# EZR32HG320F64R60 register map
File version: 4.0.0
CPU: CM0PLUS r0p1, little endian, no MPU, no FPU, 3 interrupt priority bits
Registers are 32-bit, read-write, reset 0x0 unless marked. A register's access mark holds for its fields unless they carry their own. Offsets are from the block's base; [hi:lo] are bit positions; {n}, {i} and the like mark numbered series; 'fields as' and 'values as' point back to an identical list.

## USB
Base 0x400C4000
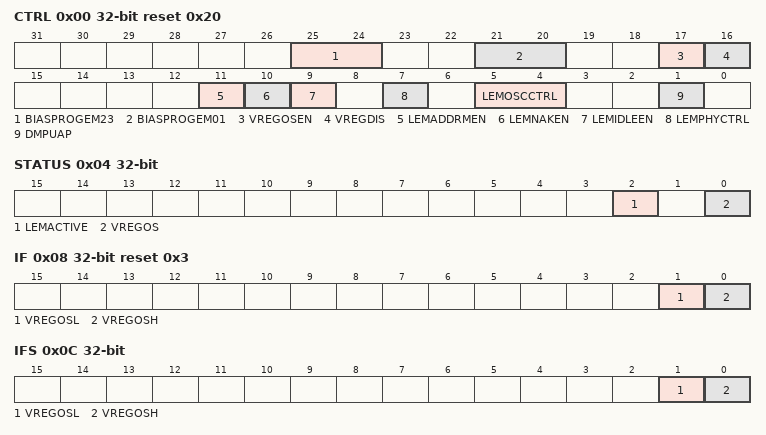
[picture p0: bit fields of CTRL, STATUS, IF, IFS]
0x00 CTRL reset 0x20 — System Control Register
  [25:24] BIASPROGEM23 — Regulator Bias Programming Value in EM2/3
  [21:20] BIASPROGEM01 — Regulator Bias Programming Value in EM0/1
  [17] VREGOSEN — VREGO Sense Enable
  [16] VREGDIS — Voltage Regulator Disable
  [11] LEMADDRMEN — Low Energy Mode on Device Address Mismatch Enable
  [10] LEMNAKEN — Low Energy Mode on OUT NAK Enable
  [9] LEMIDLEEN — Low Energy Mode on Bus Idle Enable
  [7] LEMPHYCTRL — Low Energy Mode USB PHY Control
  [5:4] LEMOSCCTRL — Low Energy Mode Oscillator Control
    0=NONE (Low Energy Mode has no effect on neither USBC or USHFRCO.); 1=GATE (The USBC clock is gated when Low Energy Mode is active.); 2=SUSPEND (The USBC clock is gated, and USHFRCO is suspended (if not selected as HFCLK) when Low Energy Mode is active.)
  [1] DMPUAP — DMPU Active Polarity
0x04 STATUS ro — System Status Register
  [2] LEMACTIVE — Low Energy Mode Active
  [0] VREGOS — VREGO Sense Output
0x08 IF ro reset 0x3 — Interrupt Flag Register
  [1] VREGOSL — VREGO Sense Low Interrupt Flag
  [0] VREGOSH — VREGO Sense High Interrupt Flag
0x0C IFS wo — Interrupt Flag Set Register
  [1] VREGOSL — Set VREGO Sense Low Interrupt Flag
  [0] VREGOSH — Set VREGO Sense High Interrupt Flag
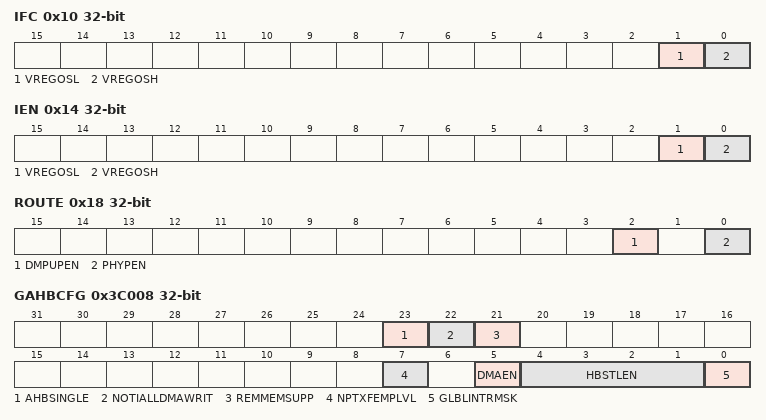
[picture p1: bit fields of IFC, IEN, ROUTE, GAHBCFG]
0x10 IFC wo — Interrupt Flag Clear Register
  [1] VREGOSL — Clear VREGO Sense Low Interrupt Flag
  [0] VREGOSH — Clear VREGO Sense High Interrupt Flag
0x14 IEN — Interrupt Enable Register
  [1] VREGOSL — VREGO Sense Low Interrupt Enable
  [0] VREGOSH — VREGO Sense High Interrupt Enable
0x18 ROUTE — I/O Routing Register
  [2] DMPUPEN — DMPU Pin Enable
  [0] PHYPEN — USB PHY Pin Enable
0x3C008 GAHBCFG — AHB Configuration Register
  [23] AHBSINGLE — AHB Single Support
  [22] NOTIALLDMAWRIT — Notify All DMA Writes
  [21] REMMEMSUPP — Remote Memory Support
  [7] NPTXFEMPLVL — Non-Periodic TxFIFO Empty Level
  [5] DMAEN — DMA Enable
  [4:1] HBSTLEN — Burst Length/Type
    0=SINGLE (Single transfer.); 1=INCR (Incrementing burst of unspecified length.); 3=INCR4 (4-beat incrementing burst.); 5=INCR8 (8-beat incrementing burst.); 7=INCR16 (16-beat incrementing burst.)
  [0] GLBLINTRMSK — Global Interrupt Mask
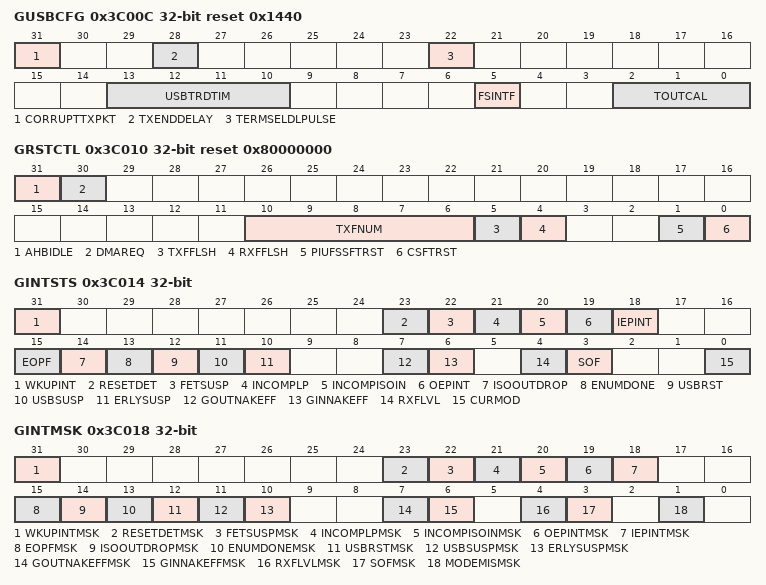
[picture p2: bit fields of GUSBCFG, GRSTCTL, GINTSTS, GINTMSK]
0x3C00C GUSBCFG reset 0x1440 — USB Configuration Register
  [31] CORRUPTTXPKT wo — Corrupt Tx packet
  [28] TXENDDELAY
  [22] TERMSELDLPULSE — TermSel DLine Pulsing Selection
  [13:10] USBTRDTIM — USB Turnaround Time
  [5] FSINTF — Full-Speed Serial Interface Select
  [2:0] TOUTCAL — Timeout Calibration
0x3C010 GRSTCTL reset 0x80000000 — Reset Register
  [31] AHBIDLE ro — AHB Master Idle
  [30] DMAREQ ro — DMA Request Signal
  [10:6] TXFNUM — TxFIFO Number
    0=F0 (Host mode: Non-periodic TxFIFO flush. Device: Tx FIFO 0 flush); 1=F1 (Host mode: Periodic TxFIFO flush. Device: TXFIFO 1 flush.); {v}=F{v} (Device mode: TXFIFO {v} flush.) (v=2..6); 16=FALL (Flush all the transmit FIFOs in device or host mode.)
  [5] TXFFLSH — TxFIFO Flush
  [4] RXFFLSH — RxFIFO Flush
  [1] PIUFSSFTRST — PIU FS Dedicated Controller Soft Reset
  [0] CSFTRST — Core Soft Reset
0x3C014 GINTSTS — Interrupt Register
  [31] WKUPINT — Resume/Remote Wakeup Detected Interrupt
  [23] RESETDET — Reset detected Interrupt
  [22] FETSUSP — Data Fetch Suspended
  [21] INCOMPLP — Incomplete Periodic Transfer
  [20] INCOMPISOIN — Incomplete Isochronous IN Transfer
  [19] OEPINT ro — OUT Endpoints Interrupt
  [18] IEPINT ro — IN Endpoints Interrupt
  [15] EOPF — End of Periodic Frame Interrupt
  [14] ISOOUTDROP — Isochronous OUT Packet Dropped Interrupt
  [13] ENUMDONE — Enumeration Done
  [12] USBRST — USB Reset
  [11] USBSUSP — USB Suspend
  [10] ERLYSUSP — Early Suspend
  [7] GOUTNAKEFF ro — Global OUT NAK Effective
  [6] GINNAKEFF ro — Global IN Non-periodic NAK Effective
  [4] RXFLVL ro — RxFIFO Non-Empty
  [3] SOF — Start of Frame
  [0] CURMOD ro — Current Mode of Operation
0x3C018 GINTMSK — Interrupt Mask Register
  [31] WKUPINTMSK — Resume/Remote Wakeup Detected Interrupt Mask
  [23] RESETDETMSK — Reset detected Interrupt Mask
  [22] FETSUSPMSK — Data Fetch Suspended Mask
  [21] INCOMPLPMSK — Incomplete Periodic Transfer Mask
  [20] INCOMPISOINMSK — Incomplete Isochronous IN Transfer Mask
  [19] OEPINTMSK — OUT Endpoints Interrupt Mask
  [18] IEPINTMSK — IN Endpoints Interrupt Mask
  [15] EOPFMSK — End of Periodic Frame Interrupt Mask
  [14] ISOOUTDROPMSK — Isochronous OUT Packet Dropped Interrupt Mask
  [13] ENUMDONEMSK — Enumeration Done Mask
  [12] USBRSTMSK — USB Reset Mask
  [11] USBSUSPMSK — USB Suspend Mask
  [10] ERLYSUSPMSK — Early Suspend Mask
  [7] GOUTNAKEFFMSK — Global OUT NAK Effective Mask
  [6] GINNAKEFFMSK — Global Non-periodic IN NAK Effective Mask
  [4] RXFLVLMSK — Receive FIFO Non-Empty Mask
  [3] SOFMSK — Start of Frame Mask
  [1] MODEMISMSK — Mode Mismatch Interrupt Mask
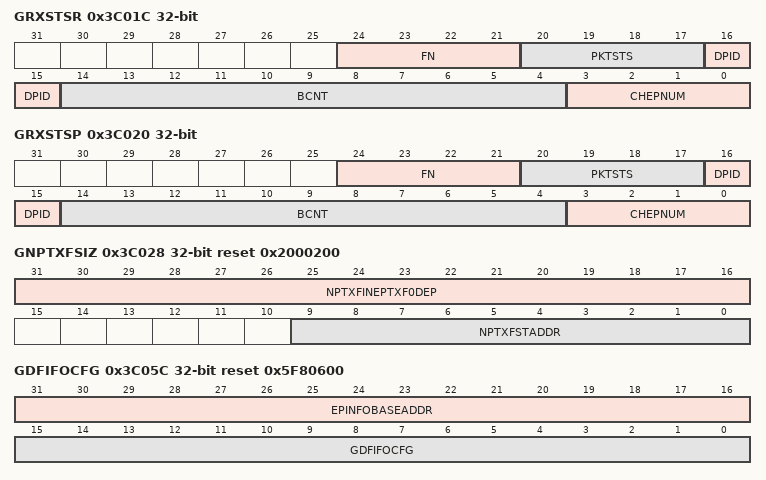
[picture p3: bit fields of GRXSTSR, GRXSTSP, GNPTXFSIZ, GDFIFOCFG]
0x3C01C GRXSTSR ro — Receive Status Debug Read Register
  [24:21] FN — Frame Number
  [20:17] PKTSTS — Packet Status (host or device)
    1=GOUTNAK (Device mode: Global OUT NAK (triggers an interrupt).); 2=PKTRCV (Host mode: IN data packet received. Device mode: OUT data packet received.); 3=XFERCOMPL (Host mode: IN transfer completed (triggers an interrupt). Device mode: OUT transfer completed (triggers an interrupt).); 4=SETUPCOMPL (Device mode: SETUP transaction completed (triggers an interrupt).); 5=TGLERR (Host mode: Data toggle error (triggers an interrupt).); 6=SETUPRCV (Device mode: SETUP data packet received.); 7=CHLT (Host mode: Channel halted (triggers an interrupt).)
  [16:15] DPID — Data PID (host or device)
    0=DATA0 (DATA0 PID.); 1=DATA1 (DATA1 PID.); 2=DATA2 (DATA2 PID.); 3=MDATA (MDATA PID.)
  [14:4] BCNT — Byte Count (host or device)
  [3:0] CHEPNUM — Channel Number host only / Endpoint Number
0x3C020 GRXSTSP ro — Receive Status Read and Pop Register
  fields as GRXSTSR
0x3C024 GRXFSIZ reset 0x200 — Receive FIFO Size Register
  [9:0] RXFDEP — RxFIFO Depth
0x3C028 GNPTXFSIZ reset 0x2000200 — Non-periodic Transmit FIFO Size Register
  [31:16] NPTXFINEPTXF0DEP — Non-periodic TxFIFO Depth host only / IN Endpoint TxFIFO 0 Depth
  [9:0] NPTXFSTADDR — Non-periodic Transmit RAM Start Address host only
0x3C05C GDFIFOCFG reset 0x5F80600 — Global DFIFO Configuration Register
  [31:16] EPINFOBASEADDR — Endpoint Info Base Address
  [15:0] GDFIFOCFG — DFIFO Config
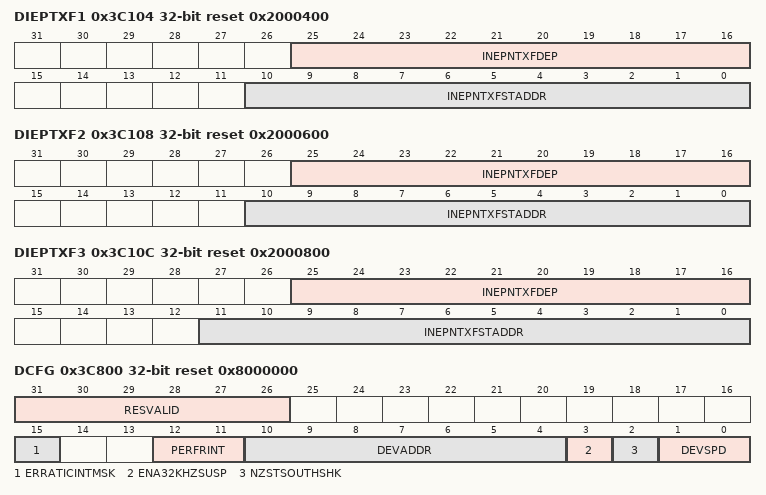
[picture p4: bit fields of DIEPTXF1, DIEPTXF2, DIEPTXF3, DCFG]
0x3C104 DIEPTXF1 reset 0x2000400 — Device IN Endpoint Transmit FIFO 1 Size Register
  [25:16] INEPNTXFDEP — IN Endpoint TxFIFO Depth
  [10:0] INEPNTXFSTADDR — IN Endpoint FIFO 1 Transmit RAM Start Address
0x3C108 DIEPTXF2 reset 0x2000600 — Device IN Endpoint Transmit FIFO 2 Size Register
  [25:16] INEPNTXFDEP — IN Endpoint TxFIFO Depth
  [10:0] INEPNTXFSTADDR — IN Endpoint FIFO 2 Transmit RAM Start Address
0x3C10C DIEPTXF3 reset 0x2000800 — Device IN Endpoint Transmit FIFO 3 Size Register
  [25:16] INEPNTXFDEP — IN Endpoint TxFIFO Depth
  [11:0] INEPNTXFSTADDR — IN Endpoint FIFO 3 Transmit RAM Start Address
0x3C800 DCFG reset 0x8000000 — Device Configuration Register
  [31:26] RESVALID — Resume Validation Period
  [15] ERRATICINTMSK
  [12:11] PERFRINT — Periodic Frame Interval
    0=80PCNT (80% of the frame interval.); 1=85PCNT (85% of the frame interval.); 2=90PCNT (90% of the frame interval.); 3=95PCNT (95% of the frame interval.)
  [10:4] DEVADDR — Device Address
  [3] ENA32KHZSUSP — Enable 32 KHz Suspend mode
  [2] NZSTSOUTHSHK — Non-Zero-Length Status OUT Handshake
  [1:0] DEVSPD — Device Speed
    2=LS (Low speed (PHY clock is 6 MHz). If you select 6 MHz LS mode, you must do a soft reset.); 3=FS (Full speed (PHY clock is 48 MHz).)
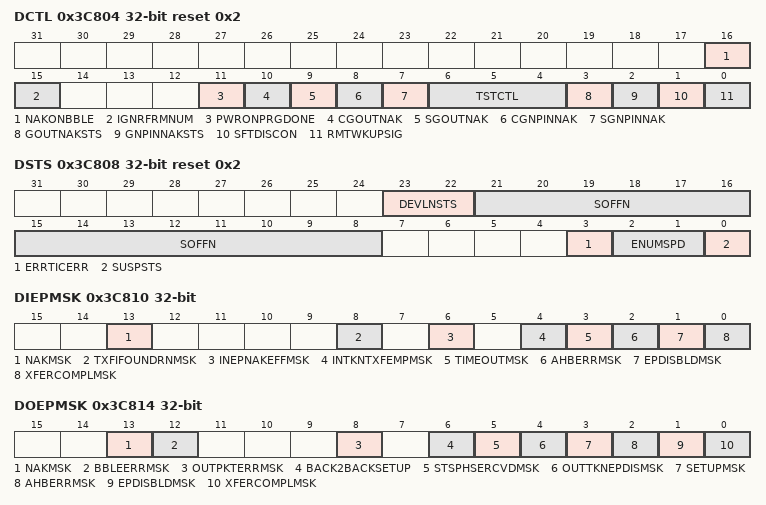
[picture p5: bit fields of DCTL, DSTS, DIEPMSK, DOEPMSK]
0x3C804 DCTL reset 0x2 — Device Control Register
  [16] NAKONBBLE — NAK on Babble Error
  [15] IGNRFRMNUM — Ignore Frame number For Isochronous End points
  [11] PWRONPRGDONE — Power-On Programming Done
  [10] CGOUTNAK wo — Clear Global OUT NAK
  [9] SGOUTNAK wo — Set Global OUT NAK
  [8] CGNPINNAK wo — Clear Global Non-periodic IN NAK
  [7] SGNPINNAK wo — Set Global Non-periodic IN NAK
  [6:4] TSTCTL — Test Control
    0=DISABLE (Test mode disabled.); 1=J (Test_J mode.); 2=K (Test_K mode.); 3=SE0NAK (Test_SE0_NAK mode.); 4=PACKET (Test_Packet mode.); 5=FORCE (Test_Force_Enable.)
  [3] GOUTNAKSTS ro — Global OUT NAK Status
  [2] GNPINNAKSTS ro — Global Non-periodic IN NAK Status
  [1] SFTDISCON — Soft Disconnect
  [0] RMTWKUPSIG — Remote Wakeup Signaling
0x3C808 DSTS ro reset 0x2 — Device Status Register
  [23:22] DEVLNSTS — Device Line Status
  [21:8] SOFFN — Frame Number of the Received SOF
  [3] ERRTICERR — Erratic Error
  [2:1] ENUMSPD — Enumerated Speed
    2=LS (Low speed (PHY clock is running at 6 MHz).); 3=FS (Full speed (PHY clock is running at 48 MHz).)
  [0] SUSPSTS — Suspend Status
0x3C810 DIEPMSK — Device IN Endpoint Common Interrupt Mask Register
  [13] NAKMSK — NAK interrupt Mask
  [8] TXFIFOUNDRNMSK — Fifo Underrun Mask
  [6] INEPNAKEFFMSK — IN Endpoint NAK Effective Mask
  [4] INTKNTXFEMPMSK — IN Token Received When TxFIFO Empty Mask
  [3] TIMEOUTMSK — Timeout Condition Mask
  [2] AHBERRMSK — AHB Error Mask
  [1] EPDISBLDMSK — Endpoint Disabled Interrupt Mask
  [0] XFERCOMPLMSK — Transfer Completed Interrupt Mask
0x3C814 DOEPMSK — Device OUT Endpoint Common Interrupt Mask Register
  [13] NAKMSK — NAK interrupt Mask
  [12] BBLEERRMSK — Babble Error interrupt Mask
  [8] OUTPKTERRMSK — OUT Packet Error Mask
  [6] BACK2BACKSETUP — Back-to-Back SETUP Packets Received Mask
  [5] STSPHSERCVDMSK — Status Phase Received Mask
  [4] OUTTKNEPDISMSK — OUT Token Received when Endpoint Disabled Mask
  [3] SETUPMSK — SETUP Phase Done Mask
  [2] AHBERRMSK — AHB Error
  [1] EPDISBLDMSK — Endpoint Disabled Interrupt Mask
  [0] XFERCOMPLMSK — Transfer Completed Interrupt Mask
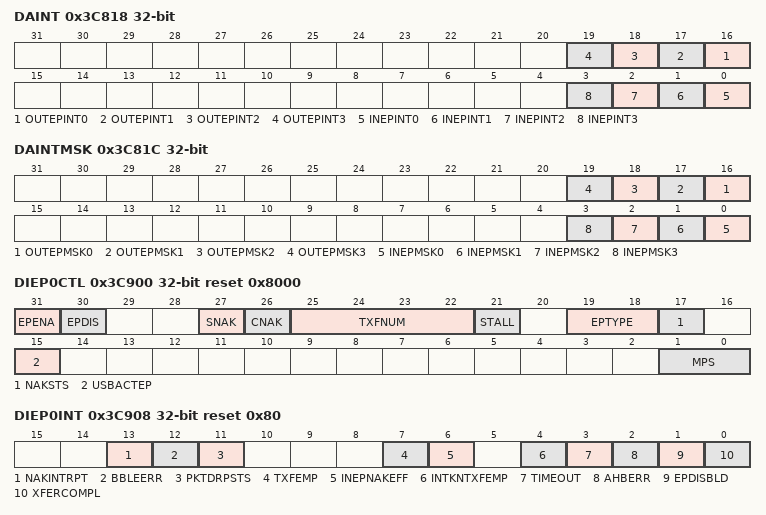
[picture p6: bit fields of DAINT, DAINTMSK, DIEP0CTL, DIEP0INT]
0x3C818 DAINT ro — Device All Endpoints Interrupt Register
  [n+16] OUTEPINT{n} (n=0..3) — OUT Endpoint {n} Interrupt Bit
  [n] INEPINT{n} (n=0..3) — IN Endpoint {n} Interrupt Bit
0x3C81C DAINTMSK — Device All Endpoints Interrupt Mask Register
  [n+16] OUTEPMSK{n} (n=0..3) — OUT Endpoint {n} Interrupt mask Bit
  [n] INEPMSK{n} (n=0..3) — IN Endpoint {n} Interrupt mask Bit
0x3C834 DIEPEMPMSK — Device IN Endpoint FIFO Empty Interrupt Mask Register
  [15:0] DIEPEMPMSK — IN EP Tx FIFO Empty Interrupt Mask Bits
0x3C900 DIEP0CTL reset 0x8000 — Device IN Endpoint 0 Control Register
  [31] EPENA — Endpoint Enable
  [30] EPDIS — Endpoint Disable
  [27] SNAK wo — Set NAK
  [26] CNAK wo — Clear NAK
  [25:22] TXFNUM — TxFIFO Number
  [21] STALL — Handshake
  [19:18] EPTYPE ro — Endpoint Type
  [17] NAKSTS ro — NAK Status
  [15] USBACTEP ro — USB Active Endpoint
  [1:0] MPS — Maximum Packet Size
    0=64B (64 bytes.); 1=32B (32 bytes.); 2=16B (16 bytes.); 3=8B (8 bytes.)
0x3C908 DIEP0INT reset 0x80 — Device IN Endpoint 0 Interrupt Register
  [13] NAKINTRPT — NAK Interrupt
  [12] BBLEERR — NAK Interrupt
  [11] PKTDRPSTS — Packet Drop Status
  [7] TXFEMP ro — Transmit FIFO Empty
  [6] INEPNAKEFF — IN Endpoint NAK Effective
  [4] INTKNTXFEMP — IN Token Received When TxFIFO is Empty
  [3] TIMEOUT — Timeout Condition
  [2] AHBERR — AHB Error
  [1] EPDISBLD — Endpoint Disabled Interrupt
  [0] XFERCOMPL — Transfer Completed Interrupt
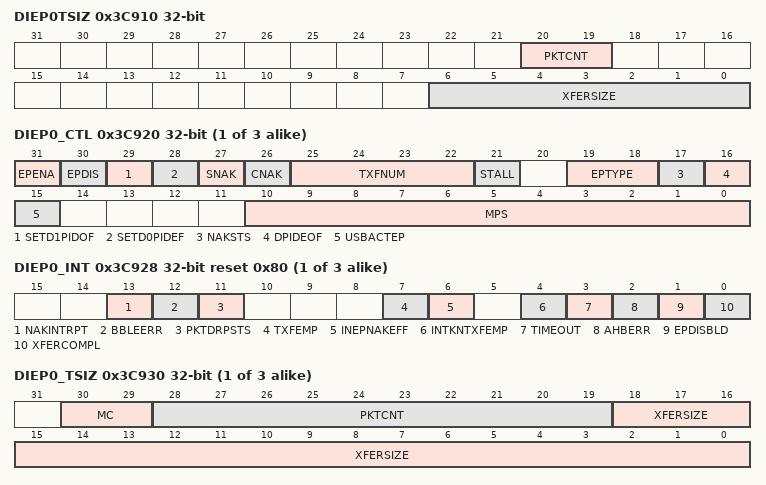
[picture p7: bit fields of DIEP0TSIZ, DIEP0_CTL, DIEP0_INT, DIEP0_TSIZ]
0x3C910 DIEP0TSIZ — Device IN Endpoint 0 Transfer Size Register
  [20:19] PKTCNT — Packet Count
  [6:0] XFERSIZE — Transfer Size
0x3C914 DIEP0DMAADDR — Device IN Endpoint 0 DMA Address Register
  [31:0] DIEP0DMAADDR — DMA Address
0x3C918 DIEP0TXFSTS ro reset 0x200 — Device IN Endpoint 0 Transmit FIFO Status Register
  [15:0] SPCAVAIL — TxFIFO Space Available
{0x3C920+0x20*i} DIEP{i}_CTL (i=0..2) — Device IN Endpoint x+1 Control Register
  [31] EPENA — Endpoint Enable
  [30] EPDIS — Endpoint Disable
  [29] SETD1PIDOF wo — Set DATA1 PID / Odd Frame
  [28] SETD0PIDEF wo — Set DATA0 PID / Even Frame
  [27] SNAK wo — Set NAK
  [26] CNAK wo — Clear NAK
  [25:22] TXFNUM — TxFIFO Number
  [21] STALL — Handshake
  [19:18] EPTYPE — Endpoint Type
    0=CONTROL (Control Endpoint.); 1=ISO (Isochronous Endpoint.); 2=BULK (Bulk Endpoint.); 3=INT (Interrupt Endpoint.)
  [17] NAKSTS ro — NAK Status
  [16] DPIDEOF ro — Endpoint Data PID / Even or Odd Frame
  [15] USBACTEP — USB Active Endpoint
  [10:0] MPS — Maximum Packet Size
{0x3C928+0x20*i} DIEP{i}_INT reset 0x80 (i=0..2) — Device IN Endpoint x+1 Interrupt Register
  fields as DIEP0INT
{0x3C930+0x20*i} DIEP{i}_TSIZ (i=0..2) — Device IN Endpoint x+1 Transfer Size Register
  [30:29] MC — Multi Count
  [28:19] PKTCNT — Packet Count
  [18:0] XFERSIZE — Transfer Size
{0x3C934+0x20*i} DIEP{i}_DMAADDR (i=0..2) — Device IN Endpoint x+1 DMA Address Register
  [31:0] DMAADDR — DMA Address
{0x3C938+0x20*i} DIEP{i}_TXFSTS ro reset 0x200 (i=0..2) — Device IN Endpoint x+1 Transmit FIFO Status Register
  [15:0] SPCAVAIL — TxFIFO Space Available
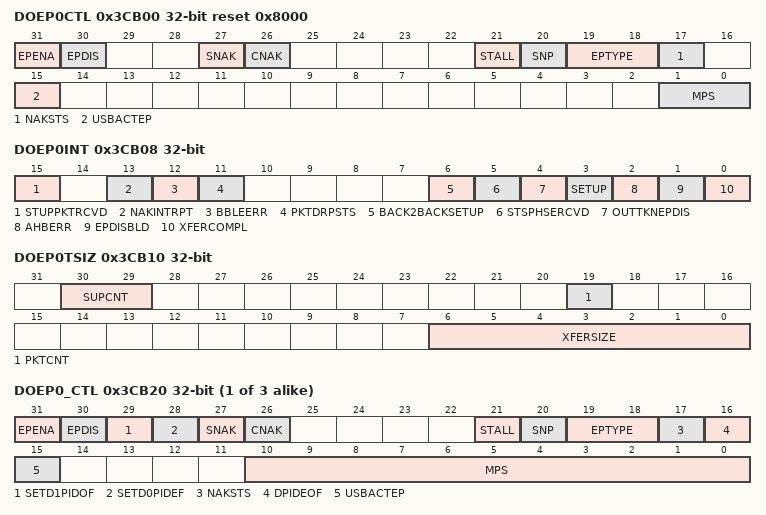
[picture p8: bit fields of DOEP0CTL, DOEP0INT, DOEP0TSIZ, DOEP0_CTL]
0x3CB00 DOEP0CTL reset 0x8000 — Device OUT Endpoint 0 Control Register
  [31] EPENA — Endpoint Enable
  [30] EPDIS ro — Endpoint Disable
  [27] SNAK wo — Set NAK
  [26] CNAK wo — Clear NAK
  [21] STALL — Handshake
  [20] SNP — Snoop Mode
  [19:18] EPTYPE ro — Endpoint Type
  [17] NAKSTS ro — NAK Status
  [15] USBACTEP ro — USB Active Endpoint
  [1:0] MPS ro — Maximum Packet Size
    values as DIEP0CTL.MPS
0x3CB08 DOEP0INT — Device OUT Endpoint 0 Interrupt Register
  [15] STUPPKTRCVD — Setup Packet Received
  [13] NAKINTRPT — NAK Interrupt
  [12] BBLEERR — NAK Interrupt
  [11] PKTDRPSTS — Packet Drop Status
  [6] BACK2BACKSETUP — Back-to-Back SETUP Packets Received
  [5] STSPHSERCVD — Status Phase Received For Control Write
  [4] OUTTKNEPDIS — OUT Token Received When Endpoint Disabled
  [3] SETUP — Setup Phase Done
  [2] AHBERR — AHB Error
  [1] EPDISBLD — Endpoint Disabled Interrupt
  [0] XFERCOMPL — Transfer Completed Interrupt
0x3CB10 DOEP0TSIZ — Device OUT Endpoint 0 Transfer Size Register
  [30:29] SUPCNT — SETUP Packet Count
  [19] PKTCNT — Packet Count
  [6:0] XFERSIZE — Transfer Size
0x3CB14 DOEP0DMAADDR — Device OUT Endpoint 0 DMA Address Register
  [31:0] DOEP0DMAADDR — DMA Address
{0x3CB20+0x20*i} DOEP{i}_CTL (i=0..2) — Device OUT Endpoint x+1 Control Register
  [31] EPENA — Endpoint Enable
  [30] EPDIS — Endpoint Disable
  [29] SETD1PIDOF wo — Set DATA1 PID / Odd Frame
  [28] SETD0PIDEF wo — Set DATA0 PID / Even Frame
  [27] SNAK wo — Set NAK
  [26] CNAK wo — Clear NAK
  [21] STALL — STALL Handshake
  [20] SNP — Snoop Mode
  [19:18] EPTYPE — Endpoint Type
    values as DIEP0_CTL.EPTYPE
  [17] NAKSTS ro — NAK Status
  [16] DPIDEOF ro — Endpoint Data PID / Even-odd Frame
  [15] USBACTEP — USB Active Endpoint
  [10:0] MPS — Maximum Packet Size
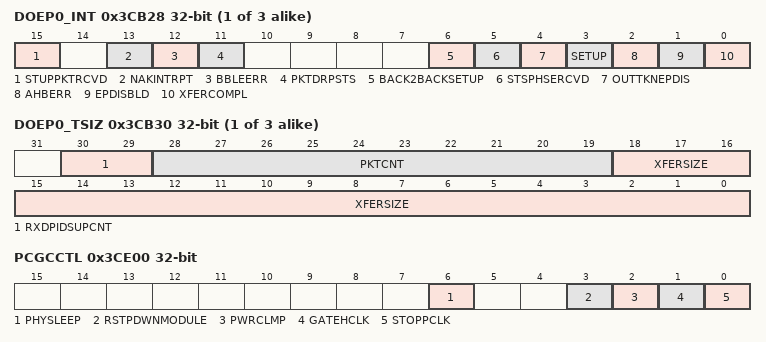
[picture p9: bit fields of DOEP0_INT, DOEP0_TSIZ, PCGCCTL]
{0x3CB28+0x20*i} DOEP{i}_INT (i=0..2) — Device OUT Endpoint x+1 Interrupt Register
  [15] STUPPKTRCVD — Setup Packet Received
  [13] NAKINTRPT — NAK Interrupt
  [12] BBLEERR — Babble Error
  [11] PKTDRPSTS — Packet Drop Status
  [6] BACK2BACKSETUP — Back-to-Back SETUP Packets Received
  [5] STSPHSERCVD — Status Phase Received For Control Write
  [4] OUTTKNEPDIS — OUT Token Received When Endpoint Disabled
  [3] SETUP — Setup Phase Done
  [2] AHBERR — AHB Error
  [1] EPDISBLD — Endpoint Disabled Interrupt
  [0] XFERCOMPL — Transfer Completed Interrupt
{0x3CB30+0x20*i} DOEP{i}_TSIZ (i=0..2) — Device OUT Endpoint x+1 Transfer Size Register
  [30:29] RXDPIDSUPCNT ro — Receive Data PID / SETUP Packet Count
    0=DATA0 (DATA0 PID.); 1=DATA2 (DATA2 PID / 1 Packet.); 2=DATA1 (DATA1 PID / 2 Packets.); 3=MDATA (MDATA PID / 3 Packets.)
  [28:19] PKTCNT — Packet Count
  [18:0] XFERSIZE — Transfer Size
{0x3CB34+0x20*i} DOEP{i}_DMAADDR (i=0..2) — Device OUT Endpoint x+1 DMA Address Register
  [31:0] DMAADDR — DMA Address
0x3CE00 PCGCCTL — Power and Clock Gating Control Register
  [6] PHYSLEEP ro — PHY In Sleep
  [3] RSTPDWNMODULE — Reset Power-Down Modules
  [2] PWRCLMP — Power Clamp
  [1] GATEHCLK
  [0] STOPPCLK — Stop PHY clock

## Notices in the file
# License
Copyright 2021 Silicon Laboratories Inc. www.silabs.com
SPDX-License-Identifier: Zlib
The licensor of this software is Silicon Laboratories Inc.
This software is provided 'as-is', without any express or implied
warranty. In no event will the authors be held liable for any damages
arising from the use of this software.
Permission is granted to anyone to use this software for any purpose,
including commercial applications, and to alter it and redistribute it
freely, subject to the following restrictions:
1. The origin of this software must not be misrepresented; you must not
claim that you wrote the original software. If you use this software
in a product, an acknowledgment in the product documentation would be
appreciated but is not required.
2. Altered source versions must be plainly marked as such, and must not be
misrepresented as being the original software.
3. This notice may not be removed or altered from any source distribution.
